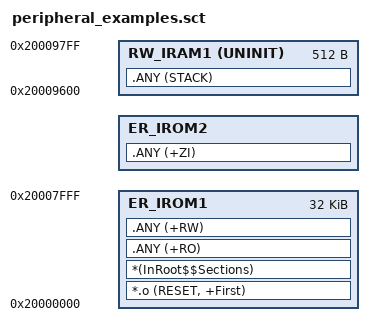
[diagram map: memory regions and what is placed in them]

LR_IROM1 0x20000000 0x00009800  {

    ER_IROM1 0x20000000 0x00008000  {
        *.o (RESET, +First)
        *(InRoot$$Sections)
        .ANY (+RO)
        .ANY (+RW)
    }
  
    ER_IROM2 +0  {
     .ANY (+ZI)
    }

    RW_IRAM1 (0x20009800 - 0x200) UNINIT 0x200 {         ; Stack
        .ANY (STACK)
    }

}

